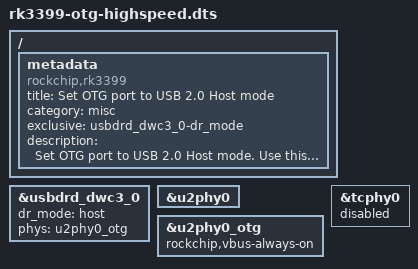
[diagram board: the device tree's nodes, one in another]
/dts-v1/;
/plugin/;

/ {
	metadata {
		title = "Set OTG port to USB 2.0 Host mode";
		compatible = "rockchip,rk3399";
		category = "misc";
		exclusive = "usbdrd_dwc3_0-dr_mode";
		description = "Set OTG port to USB 2.0 Host mode.
Use this when you want to connect USB 2.0 devices.";
	};
};

&usbdrd_dwc3_0 {
	status = "okay";
	dr_mode = "host";
	phys = <&u2phy0_otg>;
	phy-names = "usb2-phy";
	/delete-property/ extcon;
};

&u2phy0 {
	status = "okay";
};

&u2phy0_otg {
	status = "okay";
	rockchip,vbus-always-on;
	/delete-property/ vbus-supply;
};

&tcphy0 {
	status = "disabled";
};
